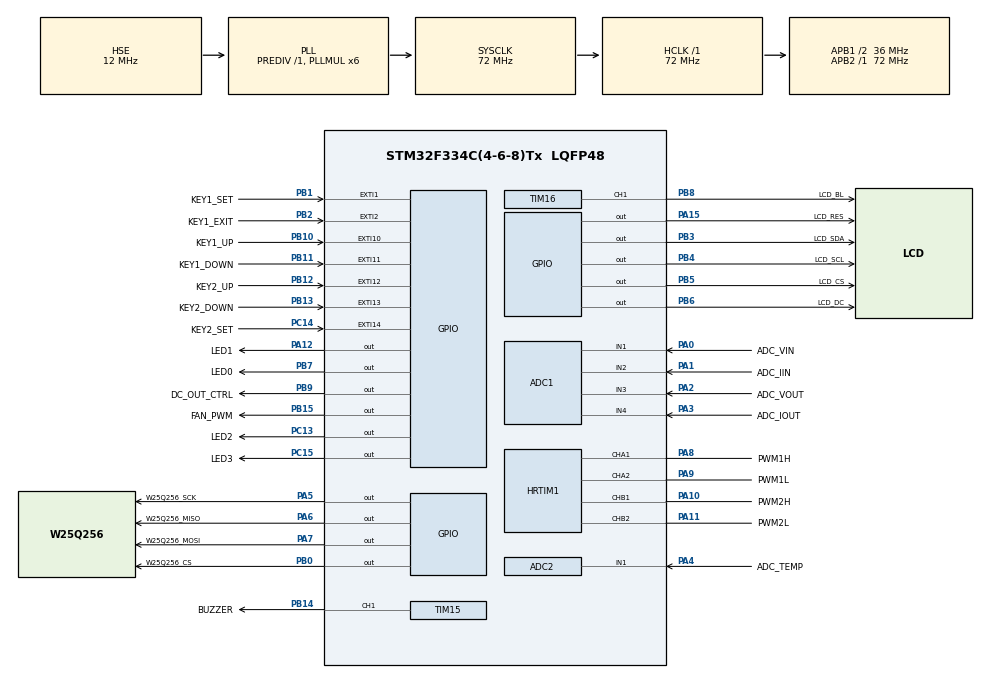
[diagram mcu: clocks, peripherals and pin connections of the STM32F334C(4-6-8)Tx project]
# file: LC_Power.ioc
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ADC1.Channel-5\#ChannelRegularConversion=ADC_CHANNEL_1
ADC1.Channel-6\#ChannelRegularConversion=ADC_CHANNEL_2
ADC1.Channel-7\#ChannelRegularConversion=ADC_CHANNEL_3
ADC1.Channel-8\#ChannelRegularConversion=ADC_CHANNEL_4
ADC1.ClockPrescaler=ADC_CLOCK_SYNC_PCLK_DIV4
ADC1.ContinuousConvMode=DISABLE
ADC1.DMAContinuousRequests=ENABLE
ADC1.EOCSelection=ADC_EOC_SEQ_CONV
ADC1.EnableInjectedConversion=DISABLE
ADC1.EnableRegularConversion=ENABLE
ADC1.ExternalTrigConv=ADC_EXTERNALTRIGCONVHRTIM_TRG1
ADC1.NbrOfConversion=4
ADC1.NbrOfConversionFlag=1
ADC1.Offset-5\#ChannelRegularConversion=0
ADC1.Offset-6\#ChannelRegularConversion=0
ADC1.Offset-7\#ChannelRegularConversion=0
ADC1.Offset-8\#ChannelRegularConversion=0
ADC1.OffsetNumber-5\#ChannelRegularConversion=ADC_OFFSET_NONE
ADC1.OffsetNumber-6\#ChannelRegularConversion=ADC_OFFSET_NONE
ADC1.OffsetNumber-7\#ChannelRegularConversion=ADC_OFFSET_NONE
ADC1.OffsetNumber-8\#ChannelRegularConversion=ADC_OFFSET_NONE
ADC1.Rank-5\#ChannelRegularConversion=1
ADC1.Rank-6\#ChannelRegularConversion=2
ADC1.Rank-7\#ChannelRegularConversion=3
ADC1.Rank-8\#ChannelRegularConversion=4
ADC1.Rank1_Channel=ADC_CHANNEL_1
ADC1.Rank2_Channel=ADC_CHANNEL_2
ADC1.Rank3_Channel=ADC_CHANNEL_3
ADC1.Rank4_Channel=ADC_CHANNEL_4
ADC1.SamplingTime-5\#ChannelRegularConversion=ADC_SAMPLETIME_1CYCLE_5
ADC1.SamplingTime-6\#ChannelRegularConversion=ADC_SAMPLETIME_1CYCLE_5
ADC1.SamplingTime-7\#ChannelRegularConversion=ADC_SAMPLETIME_1CYCLE_5
ADC1.SamplingTime-8\#ChannelRegularConversion=ADC_SAMPLETIME_1CYCLE_5
ADC1.SamplingTimeOPAMP-5\#ChannelRegularConversion=ADC_SAMPLETIME_7CYCLES_5
ADC1.SamplingTimeOPAMP-6\#ChannelRegularConversion=ADC_SAMPLETIME_7CYCLES_5
ADC1.SamplingTimeOPAMP-7\#ChannelRegularConversion=ADC_SAMPLETIME_7CYCLES_5
ADC1.SamplingTimeOPAMP-8\#ChannelRegularConversion=ADC_SAMPLETIME_7CYCLES_5
ADC1.SequencerNbRanks=1
ADC1.SubFamily=STM32F334x8
ADC1.master=1
ADC2.Channel-3\#ChannelRegularConversion=ADC_CHANNEL_1
ADC2.Channel-4\#ChannelRegularConversion=ADC_CHANNEL_VREFINT
ADC2.ClockPrescaler=ADC_CLOCK_SYNC_PCLK_DIV4
ADC2.ContinuousConvMode=ENABLE
ADC2.DMAContinuousRequests=ENABLE
ADC2.EOCSelection=ADC_EOC_SEQ_CONV
ADC2.EnableInjectedConversion=DISABLE
ADC2.EnableRegularConversion=ENABLE
ADC2.ExternalTrigConv=ADC_EXTERNALTRIGCONVHRTIM_TRG1
ADC2.NbrOfConversion=2
ADC2.NbrOfConversionFlag=1
ADC2.Offset-3\#ChannelRegularConversion=0
ADC2.Offset-4\#ChannelRegularConversion=0
ADC2.OffsetNumber-3\#ChannelRegularConversion=ADC_OFFSET_NONE
ADC2.OffsetNumber-4\#ChannelRegularConversion=ADC_OFFSET_NONE
ADC2.Rank-3\#ChannelRegularConversion=1
ADC2.Rank-4\#ChannelRegularConversion=2
ADC2.Rank1_Channel=ADC_CHANNEL_1
ADC2.Rank2_Channel=ADC_CHANNEL_VREFINT
ADC2.SamplingTime-3\#ChannelRegularConversion=ADC_SAMPLETIME_1CYCLE_5
ADC2.SamplingTime-4\#ChannelRegularConversion=ADC_SAMPLETIME_1CYCLE_5
ADC2.SamplingTimeOPAMP-3\#ChannelRegularConversion=ADC_SAMPLETIME_7CYCLES_5
ADC2.SamplingTimeOPAMP-4\#ChannelRegularConversion=ADC_SAMPLETIME_7CYCLES_5
ADC2.SubFamily=STM32F334x8
Dma.ADC1.0.Direction=DMA_PERIPH_TO_MEMORY
Dma.ADC1.0.Instance=DMA1_Channel1
Dma.ADC1.0.MemDataAlignment=DMA_MDATAALIGN_WORD
Dma.ADC1.0.MemInc=DMA_MINC_ENABLE
Dma.ADC1.0.Mode=DMA_CIRCULAR
Dma.ADC1.0.PeriphDataAlignment=DMA_PDATAALIGN_WORD
Dma.ADC1.0.PeriphInc=DMA_PINC_DISABLE
Dma.ADC1.0.Priority=DMA_PRIORITY_VERY_HIGH
Dma.ADC2.1.Direction=DMA_PERIPH_TO_MEMORY
Dma.ADC2.1.Instance=DMA1_Channel2
Dma.ADC2.1.MemDataAlignment=DMA_MDATAALIGN_WORD
Dma.ADC2.1.MemInc=DMA_MINC_ENABLE
Dma.ADC2.1.Mode=DMA_CIRCULAR
Dma.ADC2.1.PeriphDataAlignment=DMA_PDATAALIGN_WORD
Dma.ADC2.1.PeriphInc=DMA_PINC_DISABLE
Dma.ADC2.1.Priority=DMA_PRIORITY_LOW
Dma.Request0=ADC1
Dma.Request1=ADC2
HRTIM1.ADCTrigger1_Source1=HRTIM_ADCTRIGGEREVENT13_TIMERA_CMP3
HRTIM1.ADCTrigger2_Source1=HRTIM_ADCTRIGGEREVENT24_TIMERA_CMP3
HRTIM1.ADCTrigger_Id1=HRTIM_ADCTRIGGER_1
HRTIM1.ADCTrigger_Id2=HRTIM_ADCTRIGGER_2
HRTIM1.ADCTrigger_Id3=__NULL
HRTIM1.ADCTrigger_Id4=__NULL
HRTIM1.CompareUnit1-MasterTimer=HRTIM_COMPAREUNIT_1
HRTIM1.CompareUnit1-Output_TA1TA2=HRTIM_COMPAREUNIT_1
HRTIM1.CompareUnit1-Output_TB1TB2=HRTIM_COMPAREUNIT_1
HRTIM1.CompareUnit2-MasterTimer=HRTIM_COMPAREUNIT_2
HRTIM1.CompareUnit2-Output_TA1TA2=HRTIM_COMPAREUNIT_2
HRTIM1.CompareUnit2-Output_TB1TB2=HRTIM_COMPAREUNIT_2
HRTIM1.CompareUnit3-MasterTimer=HRTIM_COMPAREUNIT_3
HRTIM1.CompareUnit3-Output_TA1TA2=HRTIM_COMPAREUNIT_3
HRTIM1.CompareUnit3-Output_TB1TB2=HRTIM_COMPAREUNIT_3
HRTIM1.CompareUnit4-Output_TA1TA2=__NULL
HRTIM1.DeadTimeInsertion-Output_TA1TA2=HRTIM_TIMDEADTIMEINSERTION_ENABLED
HRTIM1.DeadTimeInsertion-Output_TB1TB2=HRTIM_TIMDEADTIMEINSERTION_ENABLED
HRTIM1.EnableCalibration=DLLITCalibration
HRTIM1.FallingValue-Output_TA1TA2=115
HRTIM1.FallingValue-Output_TB1TB2=115
HRTIM1.NumberADCTriggerSource1=1
HRTIM1.NumberADCTriggerSource2=1
HRTIM1.NumberResetSource1-Output_TA1TA2=1
HRTIM1.NumberResetSource1-Output_TB1TB2=1
HRTIM1.NumberResetSource2_TA=0
HRTIM1.NumberSetSource1-Output_TA1TA2=1
HRTIM1.NumberSetSource1-Output_TB1TB2=1
HRTIM1.ORingUpdateSource_ADCTrigger1=HRTIM_ADCTRIGGERUPDATE_TIMER_A
HRTIM1.ORingUpdateSource_ADCTrigger2=HRTIM_ADCTRIGGERUPDATE_TIMER_A
HRTIM1.Periode_MASTER=11520
HRTIM1.Periode_TA=11520
HRTIM1.Periode_TB=11520
HRTIM1.Polarity1-Output_TB1TB2=HRTIM_OUTPUTPOLARITY_HIGH
HRTIM1.Polarity2-Output_TB1TB2=HRTIM_OUTPUTPOLARITY_HIGH
HRTIM1.PreloadEnable-Output_TA1TA2=HRTIM_PRELOAD_ENABLED
HRTIM1.PreloadEnable-Output_TB1TB2=HRTIM_PRELOAD_ENABLED
HRTIM1.PrescalerRatio_TA=HRTIM_PRESCALERRATIO_MUL32
HRTIM1.PrescalerRatio_TB=HRTIM_PRESCALERRATIO_MUL32
HRTIM1.RepetitionUpdate-MasterTimer=HRTIM_UPDATEONREPETITION_ENABLED
HRTIM1.RepetitionUpdate-Output_TA1TA2=HRTIM_UPDATEONREPETITION_ENABLED
HRTIM1.RepetitionUpdate-Output_TB1TB2=HRTIM_UPDATEONREPETITION_ENABLED
HRTIM1.ResetOutput1_Source1-Output_TA1TA2=HRTIM_OUTPUTRESET_TIMCMP2
HRTIM1.ResetOutput1_Source1-Output_TB1TB2=HRTIM_OUTPUTRESET_TIMCMP1
HRTIM1.RisingValue-Output_TA1TA2=115
HRTIM1.RisingValue-Output_TB1TB2=115
HRTIM1.SetOutput1_Source1-Output_TA1TA2=HRTIM_OUTPUTSET_TIMCMP1
HRTIM1.SetOutput1_Source1-Output_TB1TB2=HRTIM_OUTPUTSET_TIMCMP2
Mcu.Family=STM32F3
Mcu.Name=STM32F334C(4-6-8)Tx
Mcu.Package=LQFP48
NVIC.DMA1_Channel1_IRQn=true\:0\:0\:false\:false\:true\:false\:true\:true
NVIC.DMA1_Channel2_IRQn=true\:0\:0\:false\:false\:true\:false\:true\:true
NVIC.HRTIM1_FLT_IRQn=true\:0\:0\:false\:false\:true\:true\:true\:true
NVIC.HRTIM1_Master_IRQn=true\:0\:0\:false\:false\:true\:false\:true\:true
NVIC.HRTIM1_TIMA_IRQn=true\:0\:0\:false\:false\:true\:true\:true\:true
NVIC.HRTIM1_TIMB_IRQn=true\:0\:0\:false\:false\:true\:true\:true\:true
NVIC.PriorityGroup=NVIC_PRIORITYGROUP_4
NVIC.TIM1_BRK_TIM15_IRQn=true\:0\:0\:false\:false\:true\:true\:true\:true
NVIC.TIM1_UP_TIM16_IRQn=true\:0\:0\:false\:false\:true\:true\:true\:true
NVIC.TIM2_IRQn=true\:0\:0\:false\:false\:true\:true\:true\:true
PA0.GPIO_Label=ADC_VIN
PA0.Mode=IN1-Single-Ended
PA0.Signal=ADC1_IN1
PA1.GPIO_Label=ADC_IIN
PA1.Mode=IN2-Single-Ended
PA1.Signal=ADC1_IN2
PA10.GPIO_Label=PWM2H
PA10.Mode=Output_TB1TB2
PA10.Signal=HRTIM1_CHB1
PA11.GPIO_Label=PWM2L
PA11.Mode=Output_TB1TB2
PA11.Signal=HRTIM1_CHB2
PA12.GPIO_Label=LED1
PA12.Signal=GPIO_Output
PA13.Mode=Serial_Wire
PA13.Signal=SYS_JTMS-SWDIO
PA14.Mode=Serial_Wire
PA14.Signal=SYS_JTCK-SWCLK
PA15.GPIO_Label=LCD_RES
PA15.GPIO_Speed=GPIO_SPEED_FREQ_HIGH
PA15.Signal=GPIO_Output
PA2.GPIO_Label=ADC_VOUT
PA2.Mode=IN3-Single-Ended
PA2.Signal=ADC1_IN3
PA3.GPIO_Label=ADC_IOUT
PA3.Mode=IN4-Single-Ended
PA3.Signal=ADC1_IN4
PA4.GPIO_Label=ADC_TEMP
PA4.Mode=IN1-Single-Ended
PA4.Signal=ADC2_IN1
PA5.GPIO_Label=W25Q256_SCK
PA5.Signal=GPIO_Output
PA6.GPIO_Label=W25Q256_MISO
PA6.Signal=GPIO_Output
PA7.GPIO_Label=W25Q256_MOSI
PA7.Signal=GPIO_Output
PA8.GPIO_Label=PWM1H
PA8.Mode=Output_TA1TA2
PA8.Signal=HRTIM1_CHA1
PA9.GPIO_Label=PWM1L
PA9.Mode=Output_TA1TA2
PA9.Signal=HRTIM1_CHA2
PB0.GPIO_Label=W25Q256_CS
PB0.Signal=GPIO_Output
PB1.GPIO_Label=KEY1_SET
PB1.Signal=GPXTI1
PB10.GPIO_Label=KEY1_UP
PB10.Signal=GPXTI10
PB11.GPIO_Label=KEY1_DOWN
PB11.Signal=GPXTI11
PB12.GPIO_Label=KEY2_UP
PB12.GPIO_PuPd=GPIO_PULLUP
PB12.Signal=GPXTI12
PB13.GPIO_Label=KEY2_DOWN
PB13.GPIO_PuPd=GPIO_PULLUP
PB13.Signal=GPXTI13
PB14.GPIO_Label=BUZZER
PB14.Signal=S_TIM15_CH1
PB15.GPIO_Label=FAN_PWM
PB15.Signal=GPIO_Output
PB2.GPIO_Label=KEY1_EXIT
PB2.Signal=GPXTI2
PB3.GPIO_Label=LCD_SDA
PB3.GPIO_Speed=GPIO_SPEED_FREQ_HIGH
PB3.Signal=GPIO_Output
PB4.GPIO_Label=LCD_SCL
PB4.GPIO_Speed=GPIO_SPEED_FREQ_HIGH
PB4.Signal=GPIO_Output
PB5.GPIO_Label=LCD_CS
PB5.GPIO_Speed=GPIO_SPEED_FREQ_HIGH
PB5.Signal=GPIO_Output
PB6.GPIO_Label=LCD_DC
PB6.GPIO_Speed=GPIO_SPEED_FREQ_HIGH
PB6.Signal=GPIO_Output
PB7.GPIO_Label=LED0
PB7.Signal=GPIO_Output
PB8.GPIO_Label=LCD_BL
PB8.Signal=S_TIM16_CH1
PB9.GPIO_Label=DC_OUT_CTRL
PB9.Signal=GPIO_Output
PC13.GPIO_Label=LED2
PC13.Signal=GPIO_Output
PC14\ /\ OSC32_IN.GPIO_Label=KEY2_SET
PC14\ /\ OSC32_IN.GPIO_PuPd=GPIO_PULLUP
PC14\ /\ OSC32_IN.Signal=GPXTI14
PC15\ /\ OSC32_OUT.GPIO_Label=LED3
PC15\ /\ OSC32_OUT.Signal=GPIO_Output
PF0\ /\ OSC_IN.Mode=HSE-External-Oscillator
PF0\ /\ OSC_IN.Signal=RCC_OSC_IN
PF1\ /\ OSC_OUT.Mode=HSE-External-Oscillator
PF1\ /\ OSC_OUT.Signal=RCC_OSC_OUT
ProjectManager.HeapSize=0x200
ProjectManager.StackSize=0x400
ProjectManager.TargetToolchain=MDK-ARM V5.32
RCC.AHBFreq_Value=72000000
RCC.APB1CLKDivider=RCC_HCLK_DIV2
RCC.APB1Freq_Value=36000000
RCC.APB1TimFreq_Value=72000000
RCC.APB2Freq_Value=72000000
RCC.APB2TimFreq_Value=72000000
RCC.CortexFreq_Value=72000000
RCC.HCLKFreq_Value=72000000
RCC.HRTIMSelection=RCC_HRTIM1CLK_PLLCLK
RCC.HSE_VALUE=12000000
RCC.HSI_VALUE=8000000
RCC.LSE_VALUE=32768
RCC.PLLMUL=RCC_PLL_MUL6
RCC.PLLSourceVirtual=RCC_PLLSOURCE_HSE
RCC.SYSCLKFreq_VALUE=72000000
RCC.SYSCLKSourceVirtual=RCC_SYSCLKSOURCE_PLLCLK
RCC.TIM1Selection=RCC_TIM1CLK_PLLCLK
SH.S_TIM15_CH1.0=TIM15_CH1,PWM Generation1 CH1
SH.S_TIM16_CH1.0=TIM16_CH1,PWM Generation1 CH1
STMicroelectronics.X-CUBE-ALGOBUILD.1.4.0.LibraryCcDSPOoLibraryJjDSPOoLibrary=true
TIM1.AutoReloadPreload=TIM_AUTORELOAD_PRELOAD_ENABLE
TIM1.Channel-PWM\ Generation4\ No\ Output=TIM_CHANNEL_4
TIM1.Period=360-1
TIM15.Channel-PWM\ Generation1\ CH1=TIM_CHANNEL_1
TIM16.Channel=TIM_CHANNEL_1
TIM2.Period=72000
VP_ADC2_Vref_Input.Mode=IN-Vrefint
VP_HRTIM1_VS_hrtimMasterTimerNoOutput.Mode=MasterTimer
VP_STMicroelectronics.X-CUBE-ALGOBUILD_VS_DSPOoLibraryJjLibrary_1.4.0_1.4.0.Mode=DSPOoLibraryJjLibrary
VP_TIM15_VS_ClockSourceINT.Mode=Internal
VP_TIM16_VS_ClockSourceINT.Mode=Enable_Timer
VP_TIM1_VS_ClockSourceINT.Mode=Internal
VP_TIM1_VS_no_output4.Mode=PWM Generation4 No Output
VP_TIM2_VS_ClockSourceINT.Mode=Internal
board=custom

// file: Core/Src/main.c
/* USER CODE BEGIN Header */
/**
  ******************************************************************************
  * @file           : main.c
  * @brief          : Main program body
  ******************************************************************************
  * @attention
  *
  * Copyright (c) 2026 STMicroelectronics.
  * All rights reserved.
  *
  * This software is licensed under terms that can be found in the LICENSE file
  * in the root directory of this software component.
  * If no LICENSE file comes with this software, it is provided AS-IS.
  *
  ******************************************************************************
  */
/* USER CODE END Header */
#include "main.h"
#include "adc.h"
#include "dma.h"
#include "hrtim.h"
#include "tim.h"
#include "gpio.h"

/* USER CODE BEGIN Includes */
#include "task_manager.h"
/* USER CODE END Includes */

void SystemClock_Config(void);

int main(void)
{

  /* MCU Configuration--------------------------------------------------------*/

  /* Reset of all peripherals, Initializes the Flash interface and the Systick. */
  HAL_Init();

  /* Configure the system clock */
  SystemClock_Config();

  /* Initialize all configured peripherals */
  MX_GPIO_Init();
  MX_DMA_Init();
  MX_ADC1_Init();
  MX_ADC2_Init();
  MX_HRTIM1_Init();
  MX_TIM1_Init();
  MX_TIM15_Init();
  MX_TIM16_Init();
  MX_TIM2_Init();
  /* USER CODE BEGIN 2 */
  SysCore_Init();
  /* USER CODE END 2 */

  /* Infinite loop */
  /* USER CODE BEGIN WHILE */

  while (1)
  {
    SysCore_Run();
    /* USER CODE END WHILE */

  }
}

void SystemClock_Config(void)
{
  RCC_OscInitTypeDef RCC_OscInitStruct = {0};
  RCC_ClkInitTypeDef RCC_ClkInitStruct = {0};
  RCC_PeriphCLKInitTypeDef PeriphClkInit = {0};

  /** Initializes the RCC Oscillators according to the specified parameters
  * in the RCC_OscInitTypeDef structure.
  */
  RCC_OscInitStruct.OscillatorType = RCC_OSCILLATORTYPE_HSE;
  RCC_OscInitStruct.HSEState = RCC_HSE_ON;
  RCC_OscInitStruct.HSEPredivValue = RCC_HSE_PREDIV_DIV1;
  RCC_OscInitStruct.HSIState = RCC_HSI_ON;
  RCC_OscInitStruct.PLL.PLLState = RCC_PLL_ON;
  RCC_OscInitStruct.PLL.PLLSource = RCC_PLLSOURCE_HSE;
  RCC_OscInitStruct.PLL.PLLMUL = RCC_PLL_MUL6;
  if (HAL_RCC_OscConfig(&RCC_OscInitStruct) != HAL_OK)
  {
    Error_Handler();
  }

  /** Initializes the CPU, AHB and APB buses clocks
  */
  RCC_ClkInitStruct.ClockType = RCC_CLOCKTYPE_HCLK|RCC_CLOCKTYPE_SYSCLK
                              |RCC_CLOCKTYPE_PCLK1|RCC_CLOCKTYPE_PCLK2;
  RCC_ClkInitStruct.SYSCLKSource = RCC_SYSCLKSOURCE_PLLCLK;
  RCC_ClkInitStruct.AHBCLKDivider = RCC_SYSCLK_DIV1;
  RCC_ClkInitStruct.APB1CLKDivider = RCC_HCLK_DIV2;
  RCC_ClkInitStruct.APB2CLKDivider = RCC_HCLK_DIV1;

  if (HAL_RCC_ClockConfig(&RCC_ClkInitStruct, FLASH_LATENCY_2) != HAL_OK)
  {
    Error_Handler();
  }
  PeriphClkInit.PeriphClockSelection = RCC_PERIPHCLK_HRTIM1|RCC_PERIPHCLK_TIM1;
  PeriphClkInit.Tim1ClockSelection = RCC_TIM1CLK_PLLCLK;
  PeriphClkInit.Hrtim1ClockSelection = RCC_HRTIM1CLK_PLLCLK;
  if (HAL_RCCEx_PeriphCLKConfig(&PeriphClkInit) != HAL_OK)
  {
    Error_Handler();
  }
}

void Error_Handler(void)
{
  __disable_irq();
  while (1)
  {
  }
}
